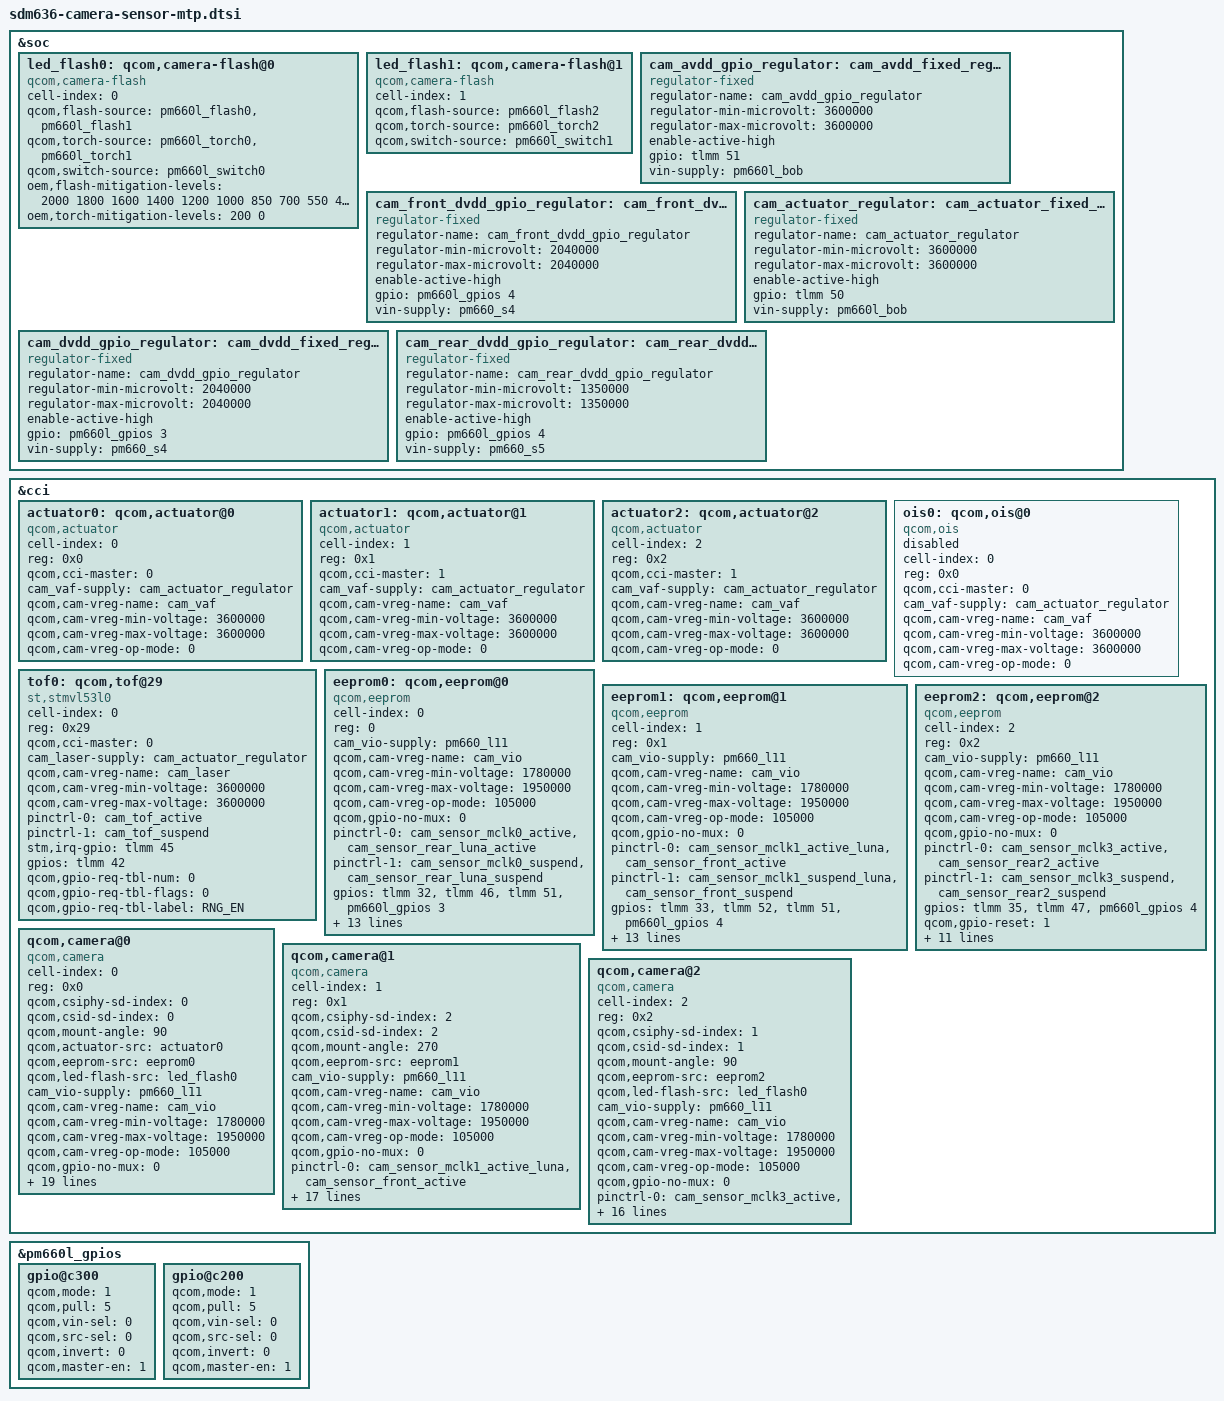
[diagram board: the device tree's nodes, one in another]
/*
 * Copyright (c) 2016-2017, The Linux Foundation. All rights reserved.
 *
 * This program is free software; you can redistribute it and/or modify
 * it under the terms of the GNU General Public License version 2 and
 * only version 2 as published by the Free Software Foundation.
 *
 * This program is distributed in the hope that it will be useful,
 * but WITHOUT ANY WARRANTY; without even the implied warranty of
 * MERCHANTABILITY or FITNESS FOR A PARTICULAR PURPOSE.  See the
 * GNU General Public License for more details.
 */

&soc {
	led_flash0: qcom,camera-flash@0 {
		cell-index = <0>;
		compatible = "qcom,camera-flash";
		qcom,flash-source = <&pm660l_flash0 &pm660l_flash1>;
		qcom,torch-source = <&pm660l_torch0 &pm660l_torch1>;
		qcom,switch-source = <&pm660l_switch0>;
		status = "ok";
               oem,flash-mitigation-levels = <2000 1800 1600 1400 1200 1000
                                               850 700 550 400 200 100 0>;
               oem,torch-mitigation-levels = <200 0>;
	};

	led_flash1: qcom,camera-flash@1 {
		cell-index = <1>;
		compatible = "qcom,camera-flash";
		qcom,flash-source = <&pm660l_flash2>;
		qcom,torch-source = <&pm660l_torch2>;
		qcom,switch-source = <&pm660l_switch1>;
		status = "ok";
	};

	cam_avdd_gpio_regulator: cam_avdd_fixed_regulator {
		compatible = "regulator-fixed";
		regulator-name = "cam_avdd_gpio_regulator";
		regulator-min-microvolt = <3600000>;
		regulator-max-microvolt = <3600000>;
		enable-active-high;
		gpio = <&tlmm 51 0>;
		vin-supply = <&pm660l_bob>;
	};

	cam_front_dvdd_gpio_regulator: cam_front_dvdd_fixed_regulator {
		compatible = "regulator-fixed";
		regulator-name = "cam_front_dvdd_gpio_regulator";
		regulator-min-microvolt = <2040000>;
		regulator-max-microvolt = <2040000>;
		enable-active-high;
		gpio = <&pm660l_gpios 4 0>;
		vin-supply = <&pm660_s4>;
	};

	cam_actuator_regulator: cam_actuator_fixed_regulator {
		compatible = "regulator-fixed";
		regulator-name = "cam_actuator_regulator";
		regulator-min-microvolt = <3600000>;
		regulator-max-microvolt = <3600000>;
		enable-active-high;
		gpio = <&tlmm 50 0>;
		vin-supply = <&pm660l_bob>;
	};

	cam_dvdd_gpio_regulator: cam_dvdd_fixed_regulator {
		compatible = "regulator-fixed";
		regulator-name = "cam_dvdd_gpio_regulator";
		regulator-min-microvolt = <2040000>;
		regulator-max-microvolt = <2040000>;
		enable-active-high;
		gpio = <&pm660l_gpios 3 0>;
		vin-supply = <&pm660_s4>;
	};

	cam_rear_dvdd_gpio_regulator: cam_rear_dvdd_fixed_regulator {
		compatible = "regulator-fixed";
		regulator-name = "cam_rear_dvdd_gpio_regulator";
		regulator-min-microvolt = <1350000>;
		regulator-max-microvolt = <1350000>;
		enable-active-high;
		gpio = <&pm660l_gpios 4 0>;
		vin-supply = <&pm660_s5>;
	};
};

&cci {
	actuator0: qcom,actuator@0 {
		cell-index = <0>;
		reg = <0x0>;
		compatible = "qcom,actuator";
		qcom,cci-master = <0>;
		cam_vaf-supply = <&cam_actuator_regulator>;
		qcom,cam-vreg-name = "cam_vaf";
		qcom,cam-vreg-min-voltage = <3600000>;
		qcom,cam-vreg-max-voltage = <3600000>;
		qcom,cam-vreg-op-mode = <0>;
	};

	actuator1: qcom,actuator@1 {
		cell-index = <1>;
		reg = <0x1>;
		compatible = "qcom,actuator";
		qcom,cci-master = <1>;
		cam_vaf-supply = <&cam_actuator_regulator>;
		qcom,cam-vreg-name = "cam_vaf";
		qcom,cam-vreg-min-voltage = <3600000>;
		qcom,cam-vreg-max-voltage = <3600000>;
		qcom,cam-vreg-op-mode = <0>;
	};

	actuator2: qcom,actuator@2 {
		cell-index = <2>;
		reg = <0x2>;
		compatible = "qcom,actuator";
		qcom,cci-master = <1>;
		cam_vaf-supply = <&cam_actuator_regulator>;
		qcom,cam-vreg-name = "cam_vaf";
		qcom,cam-vreg-min-voltage = <3600000>;
		qcom,cam-vreg-max-voltage = <3600000>;
		qcom,cam-vreg-op-mode = <0>;
	};

	ois0: qcom,ois@0 {
		cell-index = <0>;
		reg = <0x0>;
		compatible = "qcom,ois";
		qcom,cci-master = <0>;
		cam_vaf-supply = <&cam_actuator_regulator>;
		qcom,cam-vreg-name = "cam_vaf";
		qcom,cam-vreg-min-voltage = <3600000>;
		qcom,cam-vreg-max-voltage = <3600000>;
		qcom,cam-vreg-op-mode = <0>;
		status = "disabled";
	};

	tof0: qcom,tof@29{
		cell-index = <0>;
		reg = <0x29>;
		compatible = "st,stmvl53l0";
		qcom,cci-master = <0>;
		cam_laser-supply = <&cam_actuator_regulator>;
		qcom,cam-vreg-name =  "cam_laser";
		qcom,cam-vreg-min-voltage = <3600000>;
		qcom,cam-vreg-max-voltage = <3600000>;
		pinctrl-names = "cam_default", "cam_suspend";
		pinctrl-0 = <&cam_tof_active>;
		pinctrl-1 = <&cam_tof_suspend>;
		stm,irq-gpio = <&tlmm 45  0x2008>;
		gpios = <&tlmm 42 0>;
		qcom,gpio-req-tbl-num = <0>;
		qcom,gpio-req-tbl-flags = <0>;
		qcom,gpio-req-tbl-label = "RNG_EN";
	};

	eeprom0: qcom,eeprom@0 {
		cell-index = <0>;
		reg = <0>;
		compatible = "qcom,eeprom";
		cam_vio-supply = <&pm660_l11>;//nan
		//cam_vana-supply = <&cam_avdd_gpio_regulator>;//nan
		//cam_vdig-supply = <&cam_dvdd_gpio_regulator>;//nan
		qcom,cam-vreg-name = "cam_vio";
		qcom,cam-vreg-min-voltage = <1780000>;
		qcom,cam-vreg-max-voltage = <1950000>;
		qcom,cam-vreg-op-mode = <105000>;
		qcom,gpio-no-mux = <0>;
		pinctrl-names = "cam_default", "cam_suspend";
		pinctrl-0 = <&cam_sensor_mclk0_active
				 &cam_sensor_rear_luna_active>;
		pinctrl-1 = <&cam_sensor_mclk0_suspend
				 &cam_sensor_rear_luna_suspend>;
		gpios = <&tlmm 32 0>,
			<&tlmm 46 0>,
			<&tlmm 51 0>,
			<&pm660l_gpios 3 0>;
		qcom,gpio-reset = <1>;
		qcom,gpio-vana = <2>;
		qcom,gpio-vdig = <3>;
		qcom,gpio-req-tbl-num = <0 1 2 3>;
		qcom,gpio-req-tbl-flags = <1 0 0 0 >;
		qcom,gpio-req-tbl-label = "CAMIF_MCLK0",
					"CAM_RESET0",
					"CAM_VANA0",
					"CAM_VDIG0";
		qcom,sensor-position = <0>;
		qcom,sensor-mode = <0>;
		qcom,cci-master = <0>;
		status = "ok";
		clocks = <&clock_mmss MCLK0_CLK_SRC>,
				<&clock_mmss MMSS_CAMSS_MCLK0_CLK>;
		clock-names = "cam_src_clk", "cam_clk";
		qcom,clock-rates = <24000000 0>;
	};

	eeprom1: qcom,eeprom@1 {
		cell-index = <1>;
		reg = <0x1>;
		compatible = "qcom,eeprom";
		cam_vio-supply = <&pm660_l11>;	
		qcom,cam-vreg-name = "cam_vio";
		qcom,cam-vreg-min-voltage = <1780000>;
		qcom,cam-vreg-max-voltage = <1950000>;
		qcom,cam-vreg-op-mode = <105000>;
		qcom,gpio-no-mux = <0>;
		pinctrl-names = "cam_default", "cam_suspend";
		pinctrl-0 = <&cam_sensor_mclk1_active_luna
				 &cam_sensor_front_active>;
		pinctrl-1 = <&cam_sensor_mclk1_suspend_luna
				 &cam_sensor_front_suspend>;
		gpios = <&tlmm 33 0>,
			<&tlmm 52 0>,
			<&tlmm 51 0>,
			<&pm660l_gpios 4 0>;
		qcom,gpio-reset = <1>;
		qcom,gpio-vana = <2>;
		qcom,gpio-vdig = <3>;
		qcom,gpio-req-tbl-num = <0 1 2 3>;
		qcom,gpio-req-tbl-flags = <1 0 0 0>;
		qcom,gpio-req-tbl-label = "CAMIF_MCLK1",
					"CAM_RESET1",
					"CAM_VANA1",
					"CAM_VDIG1";
		qcom,sensor-position = <0>;
		qcom,sensor-mode = <0>;
		qcom,cci-master = <1>;
		status = "ok";
		clocks = <&clock_mmss MCLK1_CLK_SRC>,
			<&clock_mmss MMSS_CAMSS_MCLK1_CLK>;
		clock-names = "cam_src_clk", "cam_clk";
		qcom,clock-rates = <24000000 0>;
	};

	eeprom2: qcom,eeprom@2 {
		cell-index = <2>;
		reg = <0x2>;
		compatible = "qcom,eeprom";
		cam_vio-supply = <&pm660_l11>;
		//cam_vana-supply = <&cam_avdd_gpio_regulator>;//nan
		//cam_vdig-supply = <&cam_dvdd_gpio_regulator>;//nan
		qcom,cam-vreg-name = "cam_vio";
		qcom,cam-vreg-min-voltage = <1780000>;
		qcom,cam-vreg-max-voltage = <1950000>;
		qcom,cam-vreg-op-mode = <105000>;
		qcom,gpio-no-mux = <0>;
		pinctrl-names = "cam_default", "cam_suspend";
		pinctrl-0 = <&cam_sensor_mclk3_active
				 &cam_sensor_rear2_active>;
		pinctrl-1 = <&cam_sensor_mclk3_suspend
				 &cam_sensor_rear2_suspend>;
		gpios = <&tlmm 35 0>,
			<&tlmm 47 0>,
			<&pm660l_gpios 4 0>;
		qcom,gpio-reset = <1>;
		qcom,gpio-vana = <2>;
		qcom,gpio-req-tbl-num = <0 1 2>;
		qcom,gpio-req-tbl-flags = <1 0 0>;
		qcom,gpio-req-tbl-label = "CAMIF_MCLK3",
					"CAM_RESET2",
					"CAM_VANA2";
		qcom,sensor-position = <0>;
		qcom,sensor-mode = <0>;
		qcom,cci-master = <1>;
		status = "ok";
		clocks = <&clock_mmss MCLK3_CLK_SRC>,
			<&clock_mmss MMSS_CAMSS_MCLK3_CLK>;
		clock-names = "cam_src_clk", "cam_clk";
		qcom,clock-rates = <24000000 0>;
	};

	qcom,camera@0 {
		cell-index = <0>;
		compatible = "qcom,camera";
		reg = <0x0>;
		qcom,csiphy-sd-index = <0>;
		qcom,csid-sd-index = <0>;
		qcom,mount-angle = <90>;
		qcom,actuator-src = <&actuator0>;
		//qcom,ois-src = <&ois0>;
		qcom,eeprom-src = <&eeprom0>;
		qcom,led-flash-src = <&led_flash0>;
		cam_vio-supply = <&pm660_l11>;//nan
		qcom,cam-vreg-name = "cam_vio";
		qcom,cam-vreg-min-voltage = <1780000>;
		qcom,cam-vreg-max-voltage = <1950000>;
		qcom,cam-vreg-op-mode = <105000>;
		qcom,gpio-no-mux = <0>;
		pinctrl-names = "cam_default", "cam_suspend";
		pinctrl-0 = <&cam_sensor_mclk0_active
				 &cam_sensor_rear_luna_active>;
		pinctrl-1 = <&cam_sensor_mclk0_suspend
				 &cam_sensor_rear_luna_suspend>;
		gpios = <&tlmm 32 0>,
			<&tlmm 46 0>,
			<&tlmm 51 0>,
			<&pm660l_gpios 3 0>;
		qcom,gpio-reset = <1>;
		qcom,gpio-vana = <2>;
		qcom,gpio-vdig = <3>;
		qcom,gpio-req-tbl-num = <0 1 2 3>;
		qcom,gpio-req-tbl-flags = <1 0 0 0 >;
		qcom,gpio-req-tbl-label = "CAMIF_MCLK0",
					"CAM_RESET0",
					"CAM_VANA0",
					"CAM_VDIG0";
		qcom,sensor-position = <0>;
		qcom,sensor-mode = <0>;
		qcom,cci-master = <0>;
		status = "ok";
		clocks = <&clock_mmss MCLK0_CLK_SRC>,
				<&clock_mmss MMSS_CAMSS_MCLK0_CLK>;
		clock-names = "cam_src_clk", "cam_clk";
		qcom,clock-rates = <24000000 0>;
	};

	qcom,camera@1 {
		cell-index = <1>;
		compatible = "qcom,camera";
		reg = <0x1>;
		qcom,csiphy-sd-index = <2>;
		qcom,csid-sd-index = <2>;
		qcom,mount-angle = <270>;
		//qcom,actuator-src = <&actuator2>;
		qcom,eeprom-src = <&eeprom1>;
		cam_vio-supply = <&pm660_l11>;	
		qcom,cam-vreg-name = "cam_vio";
		qcom,cam-vreg-min-voltage = <1780000>;
		qcom,cam-vreg-max-voltage = <1950000>;
		qcom,cam-vreg-op-mode = <105000>;
		qcom,gpio-no-mux = <0>;
		pinctrl-names = "cam_default", "cam_suspend";
		pinctrl-0 = <&cam_sensor_mclk1_active_luna
				 &cam_sensor_front_active>;
		pinctrl-1 = <&cam_sensor_mclk1_suspend_luna
				 &cam_sensor_front_suspend>;
		gpios = <&tlmm 33 0>,
			<&tlmm 52 0>,
			<&tlmm 51 0>,
			<&pm660l_gpios 4 0>;
		qcom,gpio-reset = <1>;
		qcom,gpio-vana = <2>;
		qcom,gpio-vdig = <3>;
		qcom,gpio-req-tbl-num = <0 1 2 3>;
		qcom,gpio-req-tbl-flags = <1 0 0 0 >;
		qcom,gpio-req-tbl-label = "CAMIF_MCLK1",
					"CAM_RESET1",
					"CAM_VANA1",
					"CAM_VDIG1";
		qcom,sensor-position = <0>;
		qcom,sensor-mode = <0>;
		qcom,cci-master = <1>;
		status = "ok";
		clocks = <&clock_mmss MCLK1_CLK_SRC>,
			<&clock_mmss MMSS_CAMSS_MCLK1_CLK>;
		clock-names = "cam_src_clk", "cam_clk";
		qcom,clock-rates = <24000000 0>;
	};


	qcom,camera@2 {
		cell-index = <2>;
		compatible = "qcom,camera";
		reg = <0x2>;
		qcom,csiphy-sd-index = <1>;
		qcom,csid-sd-index = <1>;
		qcom,mount-angle = <90>;
		qcom,eeprom-src = <&eeprom2>;
		qcom,led-flash-src = <&led_flash0>;
		cam_vio-supply = <&pm660_l11>;
		qcom,cam-vreg-name = "cam_vio";
		qcom,cam-vreg-min-voltage = <1780000>;
		qcom,cam-vreg-max-voltage = <1950000>;
		qcom,cam-vreg-op-mode = <105000>;
		qcom,gpio-no-mux = <0>;
		pinctrl-names = "cam_default", "cam_suspend";
		pinctrl-0 = <&cam_sensor_mclk3_active
				 &cam_sensor_rear2_active>;
		pinctrl-1 = <&cam_sensor_mclk3_suspend
				 &cam_sensor_rear2_suspend>;
		gpios = <&tlmm 35 0>,
			<&tlmm 47 0>,
			<&pm660l_gpios 4 0>;
		qcom,gpio-reset = <1>;
		qcom,gpio-vana = <2>;
		qcom,gpio-req-tbl-num = <0 1 2>;
		qcom,gpio-req-tbl-flags = <1 0 0>;
		qcom,gpio-req-tbl-label = "CAMIF_MCLK3",
					"CAM_RESET2",
					"CAM_VANA2";
		qcom,sensor-position = <0>;
		qcom,sensor-mode = <0>;
		qcom,cci-master = <1>;
		status = "ok";
		clocks = <&clock_mmss MCLK3_CLK_SRC>,
			<&clock_mmss MMSS_CAMSS_MCLK3_CLK>;
		clock-names = "cam_src_clk", "cam_clk";
		qcom,clock-rates = <24000000 0>;

	};
};

&pm660l_gpios {
	gpio@c300 { /* GPIO4 -CAMERA SENSOR 0 VDIG*/
		qcom,mode = <1>;                /* Output */
		qcom,pull = <5>;                /* No Pull */
		qcom,vin-sel = <0>;             /* VIN1 GPIO_LV */
		qcom,src-sel = <0>;             /* GPIO */
		qcom,invert = <0>;              /* Invert */
		qcom,master-en = <1>;           /* Enable GPIO */
		status = "ok";
	};

	gpio@c200 { /* GPIO3 -CAMERA SENSOR 2 VDIG*/
		qcom,mode = <1>;                /* Output */
		qcom,pull = <5>;                /* No Pull */
		qcom,vin-sel = <0>;             /* VIN1 GPIO_LV */
		qcom,src-sel = <0>;             /* GPIO */
		qcom,invert = <0>;              /* Invert */
		qcom,master-en = <1>;           /* Enable GPIO */
		status = "ok";
	};
};
